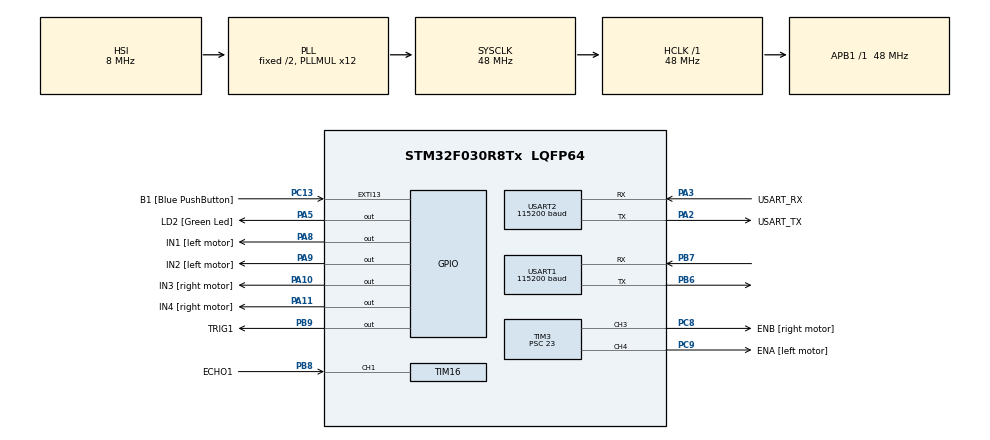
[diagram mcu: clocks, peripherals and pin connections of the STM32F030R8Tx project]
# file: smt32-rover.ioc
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FREERTOS.Tasks01=defaultTask,0,128,StartDefaultTask,Default,NULL
FREERTOS.configUSE_IDLE_HOOK=1
IWDG.Prescaler=IWDG_PRESCALER_16
Mcu.Family=STM32F0
Mcu.Name=STM32F030R8Tx
Mcu.Package=LQFP64
NVIC.EXTI4_15_IRQn=true\:3\:0\:false\:false\:true\:true\:true
NVIC.TIM16_IRQn=true\:3\:0\:false\:false\:true\:true\:true
NVIC.TIM1_BRK_UP_TRG_COM_IRQn=true\:0\:0\:false\:false\:true\:false\:false
NVIC.TimeBase=TIM1_BRK_UP_TRG_COM_IRQn
NVIC.TimeBaseIP=TIM1
NVIC.USART1_IRQn=true\:3\:0\:false\:false\:true\:true\:true
NVIC.USART2_IRQn=true\:3\:0\:false\:false\:true\:true\:true
PA10.GPIO_Label=IN3 [right motor]
PA10.Signal=GPIO_Output
PA11.GPIO_Label=IN4 [right motor]
PA11.Signal=GPIO_Output
PA13.GPIO_Label=TMS
PA13.Mode=Serial_Wire
PA13.Signal=SYS_SWDIO
PA14.GPIO_Label=TCK
PA14.Mode=Serial_Wire
PA14.Signal=SYS_SWCLK
PA2.GPIO_Label=USART_TX
PA2.GPIO_Mode=GPIO_MODE_AF_PP
PA2.GPIO_PuPd=GPIO_NOPULL
PA2.GPIO_Speed=GPIO_SPEED_FREQ_LOW
PA2.Mode=Asynchronous
PA2.Signal=USART2_TX
PA3.GPIO_Label=USART_RX
PA3.GPIO_Mode=GPIO_MODE_AF_PP
PA3.GPIO_PuPd=GPIO_NOPULL
PA3.GPIO_Speed=GPIO_SPEED_FREQ_LOW
PA3.Mode=Asynchronous
PA3.Signal=USART2_RX
PA5.GPIO_Label=LD2 [Green Led]
PA5.GPIO_Mode=GPIO_MODE_OUTPUT_PP
PA5.GPIO_PuPd=GPIO_NOPULL
PA5.GPIO_Speed=GPIO_SPEED_FREQ_LOW
PA5.Signal=GPIO_Output
PA8.GPIO_Label=IN1 [left motor]
PA8.Signal=GPIO_Output
PA9.GPIO_Label=IN2 [left motor]
PA9.Signal=GPIO_Output
PB6.Mode=Asynchronous
PB6.Signal=USART1_TX
PB7.Mode=Asynchronous
PB7.Signal=USART1_RX
PB8.GPIO_Label=ECHO1
PB8.Signal=S_TIM16_CH1
PB9.GPIO_Label=TRIG1
PB9.Signal=GPIO_Output
PC13.GPIO_Label=B1 [Blue PushButton]
PC13.GPIO_ModeDefaultEXTI=GPIO_MODE_IT_FALLING
PC13.Signal=GPXTI13
PC14-OSC32_IN.Mode=LSE-External-Oscillator
PC14-OSC32_IN.Signal=RCC_OSC32_IN
PC15-OSC32_OUT.Mode=LSE-External-Oscillator
PC15-OSC32_OUT.Signal=RCC_OSC32_OUT
PC8.GPIO_Label=ENB [right motor]
PC8.Signal=S_TIM3_CH3
PC9.GPIO_Label=ENA [left motor]
PC9.Signal=S_TIM3_CH4
PF0-OSC_IN.Mode=HSE-External-Clock-Source
PF0-OSC_IN.Signal=RCC_OSC_IN
PF1-OSC_OUT.Signal=RCC_OSC_OUT
ProjectManager.HeapSize=0x200
ProjectManager.StackSize=0x400
ProjectManager.TargetToolchain=TrueSTUDIO
RCC.AHBFreq_Value=48000000
RCC.APB1Freq_Value=48000000
RCC.APB1TimFreq_Value=48000000
RCC.HCLKFreq_Value=48000000
RCC.PLLMUL=RCC_PLL_MUL12
RCC.SYSCLKFreq_VALUE=48000000
RCC.SYSCLKSource=RCC_SYSCLKSOURCE_PLLCLK
SH.S_TIM16_CH1.0=TIM16_CH1,Input_Capture1_from_TI1
SH.S_TIM3_CH3.0=TIM3_CH3,PWM Generation3 CH3
SH.S_TIM3_CH4.0=TIM3_CH4,PWM Generation4 CH4
TIM16.AutoReloadPreload=TIM_AUTORELOAD_PRELOAD_DISABLE
TIM16.Channel=TIM_CHANNEL_1
TIM16.ICPolarity_CH1=TIM_INPUTCHANNELPOLARITY_BOTHEDGE
TIM16.Period=65535
TIM16.Prescaler=19
TIM3.Channel-PWM\ Generation3\ CH3=TIM_CHANNEL_3
TIM3.Channel-PWM\ Generation4\ CH4=TIM_CHANNEL_4
TIM3.Period=200
TIM3.Prescaler=23
USART1.BaudRate=115200
USART1.Mode=MODE_TX
USART1.VirtualMode-Asynchronous=VM_ASYNC
USART2.BaudRate=115200
USART2.Mode=MODE_RX
USART2.VirtualMode-Asynchronous=VM_ASYNC
VP_FREERTOS_VS_ENABLE.Mode=Enabled
VP_IWDG_VS_IWDG.Mode=IWDG_Activate
VP_SYS_VS_tim1.Mode=TIM1
VP_TIM16_VS_ClockSourceINT.Mode=Enable_Timer
board=NUCLEO-F030R8

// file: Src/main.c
/**
  ******************************************************************************
  * @file           : main.c
  * @brief          : Main program body
  ******************************************************************************
  * This notice applies to any and all portions of this file
  * that are not between comment pairs USER CODE BEGIN and
  * USER CODE END. Other portions of this file, whether
  * inserted by the user or by software development tools
  * are owned by their respective copyright owners.
  *
  * Copyright (c) 2018 STMicroelectronics International N.V.
  * All rights reserved.
  *
  * Redistribution and use in source and binary forms, with or without
  * modification, are permitted, provided that the following conditions are met:
  *
  * 1. Redistribution of source code must retain the above copyright notice,
  *    this list of conditions and the following disclaimer.
  * 2. Redistributions in binary form must reproduce the above copyright notice,
  *    this list of conditions and the following disclaimer in the documentation
  *    and/or other materials provided with the distribution.
  * 3. Neither the name of STMicroelectronics nor the names of other
  *    contributors to this software may be used to endorse or promote products
  *    derived from this software without specific written permission.
  * 4. This software, including modifications and/or derivative works of this
  *    software, must execute solely and exclusively on microcontroller or
  *    microprocessor devices manufactured by or for STMicroelectronics.
  * 5. Redistribution and use of this software other than as permitted under
  *    this license is void and will automatically terminate your rights under
  *    this license.
  *
  * THIS SOFTWARE IS PROVIDED BY STMICROELECTRONICS AND CONTRIBUTORS "AS IS"
  * AND ANY EXPRESS, IMPLIED OR STATUTORY WARRANTIES, INCLUDING, BUT NOT
  * LIMITED TO, THE IMPLIED WARRANTIES OF MERCHANTABILITY, FITNESS FOR A
  * PARTICULAR PURPOSE AND NON-INFRINGEMENT OF THIRD PARTY INTELLECTUAL PROPERTY
  * RIGHTS ARE DISCLAIMED TO THE FULLEST EXTENT PERMITTED BY LAW. IN NO EVENT
  * SHALL STMICROELECTRONICS OR CONTRIBUTORS BE LIABLE FOR ANY DIRECT, INDIRECT,
  * INCIDENTAL, SPECIAL, EXEMPLARY, OR CONSEQUENTIAL DAMAGES (INCLUDING, BUT NOT
  * LIMITED TO, PROCUREMENT OF SUBSTITUTE GOODS OR SERVICES; LOSS OF USE, DATA,
  * OR PROFITS; OR BUSINESS INTERRUPTION) HOWEVER CAUSED AND ON ANY THEORY OF
  * LIABILITY, WHETHER IN CONTRACT, STRICT LIABILITY, OR TORT (INCLUDING
  * NEGLIGENCE OR OTHERWISE) ARISING IN ANY WAY OUT OF THE USE OF THIS SOFTWARE,
  * EVEN IF ADVISED OF THE POSSIBILITY OF SUCH DAMAGE.
  *
  ******************************************************************************
  */
#include "main.h"
#include "stm32f0xx_hal.h"
#include "cmsis_os.h"
#include "iwdg.h"
#include "tim.h"
#include "usart.h"
#include "gpio.h"

/* USER CODE BEGIN Includes */
#include "l298n.h"
/* USER CODE END Includes */

/* USER CODE BEGIN PV */
/* Private variables ---------------------------------------------------------*/
/* USER CODE END PV */

void SystemClock_Config(void);
void MX_FREERTOS_Init(void);

/* USER CODE BEGIN PFP */
/* Private function prototypes -----------------------------------------------*/

/* USER CODE END PFP */

int main(void)
{

  /* MCU Configuration----------------------------------------------------------*/

  /* Reset of all peripherals, Initializes the Flash interface and the Systick. */
  HAL_Init();

  /* Configure the system clock */
  SystemClock_Config();

  /* Initialize all configured peripherals */
  MX_GPIO_Init();
  MX_TIM3_Init();
  MX_USART2_UART_Init();
  MX_TIM16_Init();
  MX_USART1_UART_Init();
  MX_IWDG_Init();
  /* USER CODE BEGIN 2 */
  l298n_init(&htim3);
  HAL_TIM_IC_Start_IT(&htim16, TIM_CHANNEL_1);
  //RCC_APB1PeriphClockCmd(RCC_APB1Periph_USART2,ENABLE);

  /* USER CODE END 2 */

  /* Call init function for freertos objects (in freertos.c) */
  MX_FREERTOS_Init();

  /* Start scheduler */
  osKernelStart();

  /* We should never get here as control is now taken by the scheduler */

  /* Infinite loop */
  while (1)
  {

  }

}

void SystemClock_Config(void)
{

  RCC_OscInitTypeDef RCC_OscInitStruct;
  RCC_ClkInitTypeDef RCC_ClkInitStruct;
  RCC_PeriphCLKInitTypeDef PeriphClkInit;

    /**Initializes the CPU, AHB and APB busses clocks
    */
  RCC_OscInitStruct.OscillatorType = RCC_OSCILLATORTYPE_HSI|RCC_OSCILLATORTYPE_LSI;
  RCC_OscInitStruct.HSIState = RCC_HSI_ON;
  RCC_OscInitStruct.HSICalibrationValue = 16;
  RCC_OscInitStruct.LSIState = RCC_LSI_ON;
  RCC_OscInitStruct.PLL.PLLState = RCC_PLL_ON;
  RCC_OscInitStruct.PLL.PLLSource = RCC_PLLSOURCE_HSI;
  RCC_OscInitStruct.PLL.PLLMUL = RCC_PLL_MUL12;
  RCC_OscInitStruct.PLL.PREDIV = RCC_PREDIV_DIV1;
  if (HAL_RCC_OscConfig(&RCC_OscInitStruct) != HAL_OK)
  {
    _Error_Handler(__FILE__, __LINE__);
  }

    /**Initializes the CPU, AHB and APB busses clocks
    */
  RCC_ClkInitStruct.ClockType = RCC_CLOCKTYPE_HCLK|RCC_CLOCKTYPE_SYSCLK
                              |RCC_CLOCKTYPE_PCLK1;
  RCC_ClkInitStruct.SYSCLKSource = RCC_SYSCLKSOURCE_PLLCLK;
  RCC_ClkInitStruct.AHBCLKDivider = RCC_SYSCLK_DIV1;
  RCC_ClkInitStruct.APB1CLKDivider = RCC_HCLK_DIV1;

  if (HAL_RCC_ClockConfig(&RCC_ClkInitStruct, FLASH_LATENCY_1) != HAL_OK)
  {
    _Error_Handler(__FILE__, __LINE__);
  }

  PeriphClkInit.PeriphClockSelection = RCC_PERIPHCLK_USART1;
  PeriphClkInit.Usart1ClockSelection = RCC_USART1CLKSOURCE_PCLK1;
  if (HAL_RCCEx_PeriphCLKConfig(&PeriphClkInit) != HAL_OK)
  {
    _Error_Handler(__FILE__, __LINE__);
  }

    /**Configure the Systick interrupt time
    */
  HAL_SYSTICK_Config(HAL_RCC_GetHCLKFreq()/1000);

    /**Configure the Systick
    */
  HAL_SYSTICK_CLKSourceConfig(SYSTICK_CLKSOURCE_HCLK);

  /* SysTick_IRQn interrupt configuration */
  HAL_NVIC_SetPriority(SysTick_IRQn, 3, 0);
}

void HAL_TIM_PeriodElapsedCallback(TIM_HandleTypeDef *htim)
{
  if (htim->Instance == TIM1) {
    HAL_IncTick();
  }
}

void _Error_Handler(char *file, int line)
{
  /* USER CODE BEGIN Error_Handler_Debug */
  /* User can add his own implementation to report the HAL error return state */
  while(1)
  {
	  l298n_roll();
  }
  /* USER CODE END Error_Handler_Debug */
}

/************************ (C) COPYRIGHT STMicroelectronics *****END OF FILE****/

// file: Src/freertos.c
/* USER CODE BEGIN Header */
/**
 ******************************************************************************
 * File Name          : freertos.c
 * Description        : Code for freertos applications
 ******************************************************************************
 * This notice applies to any and all portions of this file
 * that are not between comment pairs USER CODE BEGIN and
 * USER CODE END. Other portions of this file, whether
 * inserted by the user or by software development tools
 * are owned by their respective copyright owners.
 *
 * Copyright (c) 2018 STMicroelectronics International N.V.
 * All rights reserved.
 *
 * Redistribution and use in source and binary forms, with or without
 * modification, are permitted, provided that the following conditions are met:
 *
 * 1. Redistribution of source code must retain the above copyright notice,
 *    this list of conditions and the following disclaimer.
 * 2. Redistributions in binary form must reproduce the above copyright notice,
 *    this list of conditions and the following disclaimer in the documentation
 *    and/or other materials provided with the distribution.
 * 3. Neither the name of STMicroelectronics nor the names of other
 *    contributors to this software may be used to endorse or promote products
 *    derived from this software without specific written permission.
 * 4. This software, including modifications and/or derivative works of this
 *    software, must execute solely and exclusively on microcontroller or
 *    microprocessor devices manufactured by or for STMicroelectronics.
 * 5. Redistribution and use of this software other than as permitted under
 *    this license is void and will automatically terminate your rights under
 *    this license.
 *
 * THIS SOFTWARE IS PROVIDED BY STMICROELECTRONICS AND CONTRIBUTORS "AS IS"
 * AND ANY EXPRESS, IMPLIED OR STATUTORY WARRANTIES, INCLUDING, BUT NOT
 * LIMITED TO, THE IMPLIED WARRANTIES OF MERCHANTABILITY, FITNESS FOR A
 * PARTICULAR PURPOSE AND NON-INFRINGEMENT OF THIRD PARTY INTELLECTUAL PROPERTY
 * RIGHTS ARE DISCLAIMED TO THE FULLEST EXTENT PERMITTED BY LAW. IN NO EVENT
 * SHALL STMICROELECTRONICS OR CONTRIBUTORS BE LIABLE FOR ANY DIRECT, INDIRECT,
 * INCIDENTAL, SPECIAL, EXEMPLARY, OR CONSEQUENTIAL DAMAGES (INCLUDING, BUT NOT
 * LIMITED TO, PROCUREMENT OF SUBSTITUTE GOODS OR SERVICES; LOSS OF USE, DATA,
 * OR PROFITS; OR BUSINESS INTERRUPTION) HOWEVER CAUSED AND ON ANY THEORY OF
 * LIABILITY, WHETHER IN CONTRACT, STRICT LIABILITY, OR TORT (INCLUDING
 * NEGLIGENCE OR OTHERWISE) ARISING IN ANY WAY OUT OF THE USE OF THIS SOFTWARE,
 * EVEN IF ADVISED OF THE POSSIBILITY OF SUCH DAMAGE.
 *
 ******************************************************************************
 */
/* USER CODE END Header */

#include "FreeRTOS.h"
#include "task.h"
#include "main.h"
#include "cmsis_os.h"

/* USER CODE BEGIN Includes */
#include "rover.h"
/* USER CODE END Includes */

osThreadId defaultTaskHandle;

void StartDefaultTask(void const * argument);

void MX_FREERTOS_Init(void); /* (MISRA C 2004 rule 8.1) */

/* Hook prototypes */
void vApplicationIdleHook(void);

void MX_FREERTOS_Init(void) {

  /* Create the thread(s) */
  /* definition and creation of defaultTask */
  osThreadDef(defaultTask, StartDefaultTask, osPriorityNormal, 0, 128);
  defaultTaskHandle = osThreadCreate(osThread(defaultTask), NULL);

  /* USER CODE BEGIN RTOS_THREADS */
	/* add threads, ... */
	rover_tasks_init();
  /* USER CODE END RTOS_THREADS */

}

void StartDefaultTask(void const * argument)
{

  /* USER CODE BEGIN StartDefaultTask */
	/* Infinite loop */
	default_task_loop();
  /* USER CODE END StartDefaultTask */
}

/************************ (C) COPYRIGHT STMicroelectronics *****END OF FILE****/
